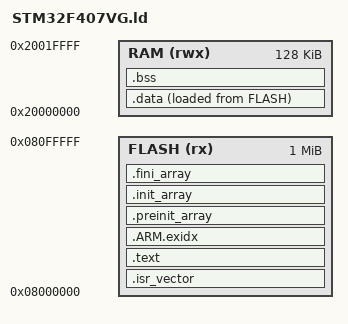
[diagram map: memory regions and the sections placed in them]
/* STM32F407VG: 1 MB flash, 128 KB SRAM (+64 KB CCM, unused here) */
ENTRY(Reset_Handler)

MEMORY
{
    FLASH (rx)  : ORIGIN = 0x08000000, LENGTH = 1024K
    RAM   (rwx) : ORIGIN = 0x20000000, LENGTH = 128K
}

_estack = ORIGIN(RAM) + LENGTH(RAM);
_min_stack_size = 0x800;

SECTIONS
{
    .isr_vector :
    {
        . = ALIGN(4);
        KEEP(*(.isr_vector))
    } > FLASH

    .text :
    {
        . = ALIGN(4);
        *(.text*)
        *(.rodata*)
        KEEP(*(.init))
        KEEP(*(.fini))
        . = ALIGN(4);
    } > FLASH

    .ARM.exidx : { *(.ARM.exidx* .gnu.linkonce.armexidx.*) } > FLASH

    .preinit_array : { PROVIDE_HIDDEN(__preinit_array_start = .); KEEP(*(.preinit_array*)); PROVIDE_HIDDEN(__preinit_array_end = .); } > FLASH
    .init_array    : { PROVIDE_HIDDEN(__init_array_start = .); KEEP(*(SORT(.init_array.*))); KEEP(*(.init_array*)); PROVIDE_HIDDEN(__init_array_end = .); } > FLASH
    .fini_array    : { PROVIDE_HIDDEN(__fini_array_start = .); KEEP(*(SORT(.fini_array.*))); KEEP(*(.fini_array*)); PROVIDE_HIDDEN(__fini_array_end = .); } > FLASH

    _sidata = LOADADDR(.data);

    .data :
    {
        . = ALIGN(4);
        _sdata = .;
        *(.data*)
        . = ALIGN(4);
        _edata = .;
    } > RAM AT > FLASH

    .bss (NOLOAD) :
    {
        . = ALIGN(4);
        _sbss = .;
        *(.bss*)
        *(COMMON)
        . = ALIGN(4);
        _ebss = .;
    } > RAM

    /* heap for newlib's _sbrk (from nosys) starts at 'end' */
    . = ALIGN(8);
    PROVIDE(end = .);
    PROVIDE(_end = .);

    ASSERT(. + _min_stack_size <= _estack, "Not enough RAM for stack")
}
